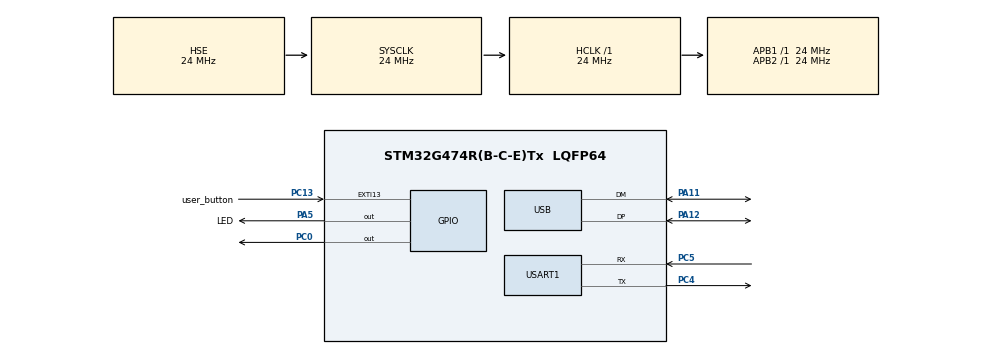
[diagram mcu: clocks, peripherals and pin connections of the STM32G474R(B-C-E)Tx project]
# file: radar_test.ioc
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Mcu.Family=STM32G4
Mcu.Name=STM32G474R(B-C-E)Tx
Mcu.Package=LQFP64
NVIC.EXTI15_10_IRQn=true\:0\:0\:false\:false\:true\:true\:true\:true
NVIC.PriorityGroup=NVIC_PRIORITYGROUP_4
NVIC.USB_LP_IRQn=true\:0\:0\:false\:false\:true\:false\:true\:true
PA11.Mode=Device
PA11.Signal=USB_DM
PA12.Mode=Device
PA12.Signal=USB_DP
PA13.Mode=Serial_Wire
PA13.Signal=SYS_JTMS-SWDIO
PA14.Mode=Serial_Wire
PA14.Signal=SYS_JTCK-SWCLK
PA5.GPIO_Label=LED
PA5.Signal=GPIO_Output
PC0.Signal=GPIO_Output
PC13.GPIO_Label=user_button
PC13.Signal=GPXTI13
PC14-OSC32_IN.Mode=LSE-External-Oscillator
PC14-OSC32_IN.Signal=RCC_OSC32_IN
PC15-OSC32_OUT.Mode=LSE-External-Oscillator
PC15-OSC32_OUT.Signal=RCC_OSC32_OUT
PC4.Mode=Asynchronous
PC4.Signal=USART1_TX
PC5.Mode=Asynchronous
PC5.Signal=USART1_RX
PF0-OSC_IN.Mode=HSE-External-Oscillator
PF0-OSC_IN.Signal=RCC_OSC_IN
PF1-OSC_OUT.Mode=HSE-External-Oscillator
PF1-OSC_OUT.Signal=RCC_OSC_OUT
ProjectManager.HeapSize=0x200
ProjectManager.StackSize=0x400
ProjectManager.TargetToolchain=CMake
RCC.ADC12Freq_Value=24000000
RCC.ADC345Freq_Value=24000000
RCC.AHBFreq_Value=24000000
RCC.APB1Freq_Value=24000000
RCC.APB1TimFreq_Value=24000000
RCC.APB2Freq_Value=24000000
RCC.APB2TimFreq_Value=24000000
RCC.CK48CLockSelection=RCC_USBCLKSOURCE_HSI48
RCC.CortexFreq_Value=24000000
RCC.EXTERNAL_CLOCK_VALUE=12288000
RCC.HCLKFreq_Value=24000000
RCC.HSE_VALUE=24000000
RCC.HSI48_VALUE=48000000
RCC.HSI_VALUE=16000000
RCC.PLLSourceVirtual=RCC_PLLSOURCE_HSE
RCC.SYSCLKFreq_VALUE=24000000
RCC.SYSCLKSource=RCC_SYSCLKSOURCE_HSE
RCC.USBFreq_Value=48000000
RCC.VCOOutputFreq_Value=192000000
USART1.VirtualMode-Asynchronous=VM_ASYNC
USB_DEVICE.CLASS_NAME_FS=CDC
USB_DEVICE.VirtualMode=Cdc
USB_DEVICE.VirtualModeFS=Cdc_FS
VP_SYS_VS_DBSignals.Mode=DisableDeadBatterySignals
VP_TIM1_VS_ClockSourceINT.Mode=Internal
VP_USB_DEVICE_VS_USB_DEVICE_CDC_FS.Mode=CDC_FS
board=custom

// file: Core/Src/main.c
/* USER CODE BEGIN Header */
/**
  ******************************************************************************
  * @file           : main.c
  * @brief          : Main program body
  ******************************************************************************
  * @attention
  *
  * Copyright (c) 2025 STMicroelectronics.
  * All rights reserved.
  *
  * This software is licensed under terms that can be found in the LICENSE file
  * in the root directory of this software component.
  * If no LICENSE file comes with this software, it is provided AS-IS.
  *
  ******************************************************************************
  */
/* USER CODE END Header */
#include "main.h"
#include "usb_device.h"

/* USER CODE BEGIN Includes */
#include "log.h"
/* USER CODE END Includes */

TIM_HandleTypeDef htim1;

UART_HandleTypeDef huart1;

void SystemClock_Config(void);
static void MX_GPIO_Init(void);
static void MX_TIM1_Init(void);
static void MX_USART1_UART_Init(void);

int main(void)
{

  /* MCU Configuration--------------------------------------------------------*/

  /* Reset of all peripherals, Initializes the Flash interface and the Systick. */
  HAL_Init();

  /* Configure the system clock */
  SystemClock_Config();

  /* Initialize all configured peripherals */
  MX_GPIO_Init();
  MX_TIM1_Init();
  MX_USART1_UART_Init();
  MX_USB_Device_Init();

  /* Infinite loop */
  /* USER CODE BEGIN WHILE */
  while (1)
  {
    // HAL_GPIO_TogglePin(LED_GPIO_Port, LED_Pin);
    // usb_printf("Hello World!\n");
    // HAL_Delay(500);
    /* USER CODE END WHILE */

  }
}

void SystemClock_Config(void)
{
  RCC_OscInitTypeDef RCC_OscInitStruct = {0};
  RCC_ClkInitTypeDef RCC_ClkInitStruct = {0};

  /** Configure the main internal regulator output voltage
  */
  HAL_PWREx_ControlVoltageScaling(PWR_REGULATOR_VOLTAGE_SCALE1);

  /** Initializes the RCC Oscillators according to the specified parameters
  * in the RCC_OscInitTypeDef structure.
  */
  RCC_OscInitStruct.OscillatorType = RCC_OSCILLATORTYPE_HSI48|RCC_OSCILLATORTYPE_HSE;
  RCC_OscInitStruct.HSEState = RCC_HSE_ON;
  RCC_OscInitStruct.HSI48State = RCC_HSI48_ON;
  RCC_OscInitStruct.PLL.PLLState = RCC_PLL_NONE;
  if (HAL_RCC_OscConfig(&RCC_OscInitStruct) != HAL_OK)
  {
    Error_Handler();
  }

  /** Initializes the CPU, AHB and APB buses clocks
  */
  RCC_ClkInitStruct.ClockType = RCC_CLOCKTYPE_HCLK|RCC_CLOCKTYPE_SYSCLK
                              |RCC_CLOCKTYPE_PCLK1|RCC_CLOCKTYPE_PCLK2;
  RCC_ClkInitStruct.SYSCLKSource = RCC_SYSCLKSOURCE_HSE;
  RCC_ClkInitStruct.AHBCLKDivider = RCC_SYSCLK_DIV1;
  RCC_ClkInitStruct.APB1CLKDivider = RCC_HCLK_DIV1;
  RCC_ClkInitStruct.APB2CLKDivider = RCC_HCLK_DIV1;

  if (HAL_RCC_ClockConfig(&RCC_ClkInitStruct, FLASH_LATENCY_0) != HAL_OK)
  {
    Error_Handler();
  }
}

static void MX_TIM1_Init(void)
{

  TIM_ClockConfigTypeDef sClockSourceConfig = {0};
  TIM_MasterConfigTypeDef sMasterConfig = {0};

  htim1.Instance = TIM1;
  htim1.Init.Prescaler = 0;
  htim1.Init.CounterMode = TIM_COUNTERMODE_UP;
  htim1.Init.Period = 65535;
  htim1.Init.ClockDivision = TIM_CLOCKDIVISION_DIV1;
  htim1.Init.RepetitionCounter = 0;
  htim1.Init.AutoReloadPreload = TIM_AUTORELOAD_PRELOAD_DISABLE;
  if (HAL_TIM_Base_Init(&htim1) != HAL_OK)
  {
    Error_Handler();
  }
  sClockSourceConfig.ClockSource = TIM_CLOCKSOURCE_INTERNAL;
  if (HAL_TIM_ConfigClockSource(&htim1, &sClockSourceConfig) != HAL_OK)
  {
    Error_Handler();
  }
  sMasterConfig.MasterOutputTrigger = TIM_TRGO_RESET;
  sMasterConfig.MasterOutputTrigger2 = TIM_TRGO2_RESET;
  sMasterConfig.MasterSlaveMode = TIM_MASTERSLAVEMODE_DISABLE;
  if (HAL_TIMEx_MasterConfigSynchronization(&htim1, &sMasterConfig) != HAL_OK)
  {
    Error_Handler();
  }

}

static void MX_USART1_UART_Init(void)
{

  huart1.Instance = USART1;
  huart1.Init.BaudRate = 115200;
  huart1.Init.WordLength = UART_WORDLENGTH_8B;
  huart1.Init.StopBits = UART_STOPBITS_1;
  huart1.Init.Parity = UART_PARITY_NONE;
  huart1.Init.Mode = UART_MODE_TX_RX;
  huart1.Init.HwFlowCtl = UART_HWCONTROL_NONE;
  huart1.Init.OverSampling = UART_OVERSAMPLING_16;
  huart1.Init.OneBitSampling = UART_ONE_BIT_SAMPLE_DISABLE;
  huart1.Init.ClockPrescaler = UART_PRESCALER_DIV1;
  huart1.AdvancedInit.AdvFeatureInit = UART_ADVFEATURE_NO_INIT;
  if (HAL_UART_Init(&huart1) != HAL_OK)
  {
    Error_Handler();
  }
  if (HAL_UARTEx_SetTxFifoThreshold(&huart1, UART_TXFIFO_THRESHOLD_1_8) != HAL_OK)
  {
    Error_Handler();
  }
  if (HAL_UARTEx_SetRxFifoThreshold(&huart1, UART_RXFIFO_THRESHOLD_1_8) != HAL_OK)
  {
    Error_Handler();
  }
  if (HAL_UARTEx_DisableFifoMode(&huart1) != HAL_OK)
  {
    Error_Handler();
  }

}

static void MX_GPIO_Init(void)
{
  GPIO_InitTypeDef GPIO_InitStruct = {0};

  /* GPIO Ports Clock Enable */
  __HAL_RCC_GPIOC_CLK_ENABLE();
  __HAL_RCC_GPIOF_CLK_ENABLE();
  __HAL_RCC_GPIOA_CLK_ENABLE();

  /*Configure GPIO pin Output Level */
  HAL_GPIO_WritePin(GPIOC, GPIO_PIN_0, GPIO_PIN_RESET);

  /*Configure GPIO pin Output Level */
  HAL_GPIO_WritePin(LED_GPIO_Port, LED_Pin, GPIO_PIN_RESET);

  /*Configure GPIO pin : user_button_Pin */
  GPIO_InitStruct.Pin = user_button_Pin;
  GPIO_InitStruct.Mode = GPIO_MODE_IT_RISING;
  GPIO_InitStruct.Pull = GPIO_NOPULL;
  HAL_GPIO_Init(user_button_GPIO_Port, &GPIO_InitStruct);

  /*Configure GPIO pin : PC0 */
  GPIO_InitStruct.Pin = GPIO_PIN_0;
  GPIO_InitStruct.Mode = GPIO_MODE_OUTPUT_PP;
  GPIO_InitStruct.Pull = GPIO_NOPULL;
  GPIO_InitStruct.Speed = GPIO_SPEED_FREQ_LOW;
  HAL_GPIO_Init(GPIOC, &GPIO_InitStruct);

  /*Configure GPIO pin : LED_Pin */
  GPIO_InitStruct.Pin = LED_Pin;
  GPIO_InitStruct.Mode = GPIO_MODE_OUTPUT_PP;
  GPIO_InitStruct.Pull = GPIO_NOPULL;
  GPIO_InitStruct.Speed = GPIO_SPEED_FREQ_LOW;
  HAL_GPIO_Init(LED_GPIO_Port, &GPIO_InitStruct);

  /* EXTI interrupt init*/
  HAL_NVIC_SetPriority(EXTI15_10_IRQn, 0, 0);
  HAL_NVIC_EnableIRQ(EXTI15_10_IRQn);

}

/* USER CODE BEGIN 4 */
void HAL_GPIO_EXTI_Callback(uint16_t GPIO_Pin){
  if(GPIO_Pin == user_button_Pin){
    HAL_GPIO_TogglePin(LED_GPIO_Port, LED_Pin);
    usb_printf("hello world\n");
  }
}

/* USER CODE END 4 */

void Error_Handler(void)
{
  __disable_irq();
  while (1)
  {
  }
}
